# CEC1702 register map
Vendor: Microchip Technology; Series: CEC1702Q; File version: 0
CPU: CM4 r1p0, little endian, MPU, FPU, 3 interrupt priority bits, 155 interrupts
Registers are 32-bit, read-write, reset 0x0 unless marked. A register's access mark holds for its fields unless they carry their own. Offsets are from the block's base; [hi:lo] are bit positions.

## WEEK — The Week Alarm Interface provides two timekeeping functions: a Week Timer and a Sub-Week Timer. Both the Week Timer and the Sub-Week Timer assert the Power-Up Event Output which automatically powers-up the system from the G3 state.
Base 0x4000AC80; register names take the prefix WEEK_
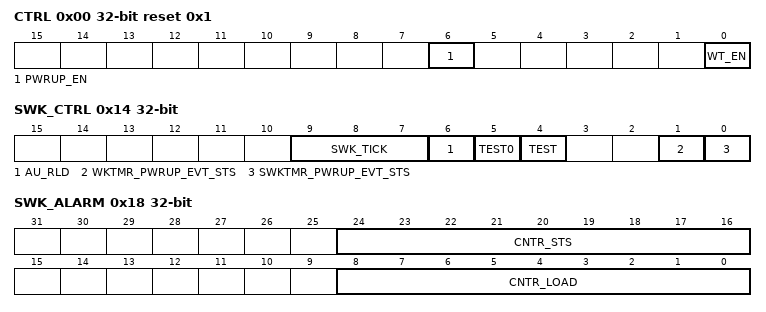
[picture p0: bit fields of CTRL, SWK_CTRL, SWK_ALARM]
0x00 CTRL reset 0x1 — Control Register
  [6] PWRUP_EN — This bit controls the state of the Power-Up Event Output and enables Week POWER-UP Event decoding in the VBAT-Powered Control Interface. 1=Power-Up Event Output Enabled. 0=Power-Up Event Output Disabled and Reset
  [0] WT_EN — The WT_EN bit is used to start and stop the Week Alarm Counter Register and the Clock Divider Register. The value in the Counter Register is held when the WT_ENABLE bit is not asserted (0) and the count is resumed from the last value when the bit is asserted (1). The 15-Bit Clock Divider is reset to 00h and the Week Alarm Interface is in its lowest power consumption state when the WT_ENABLE bit is not asserted.
0x04 ALARM_CNT — Week Alarm Counter Register
  [27:0] WK_CNTR — While the WT_ENABLE bit is 1, this register is incremented at a 1 Hz rate. Writes of this register may require one second to take effect. Reads return the current state of the register. Reads and writes complete independently of the state of WT_ENABLE.
0x08 TMR_COMP reset 0xFFFFFFF — Week Timer Compare Register
  [27:0] WK_COMP — A Week Alarm Interrupt and a Week Alarm Power-Up Event are asserted when the Week Alarm Counter Register is greater than or equal to the contents of this register. Reads and writes complete independently of the state of WT_ENABLE.
0x0C CLKDIV — Clock Divider Register
  [14:0] DIV — Reads of this register return the current state of the Week Timer 15- bit clock divider.
0x10 SS_INTR_SEL — Sub-Second Programmable Interrupt Select Register
  [3:0] SPISR — This field determines the rate at which Sub-Second interrupt events are generated.
0x14 SWK_CTRL ro — Sub-Week Control Register
  [9:7] SWK_TICK — This field selects the clock source for the Sub-Week Counter.
  [6] AU_RLD — 1= No reload occurs when the Sub-Week Counter expires. 0= Reloads the SUBWEEK_COUNTER_LOAD field into the Sub- Week Counter when the counter expires.
  [5] TEST0 — Test
  [4] TEST
  [1] WKTMR_PWRUP_EVT_STS — This bit is set to 1 when the Week Alarm Counter Register is greater than or equal the contents of the Week Timer Compare. Register and the POWERUP_EN is 1. Writes of 1 clear this bit. Writes of 0 have no effect. Note: This bit does not have to be cleared to remove a Week Timer Power-Up Event.
  [0] SWKTMR_PWRUP_EVT_STS — This bit is set to 1 when the Sub-Week Alarm Counter Register decrements from 1 to 0 and the POWERUP_EN is 1. Writes of 1 clear this bit. Writes of 0 have no effect. Note: This bit MUST be cleared to remove a Sub-Week Timer Power-Up Event.
0x18 SWK_ALARM ro — Sub-Week Alarm Counter Register
  [24:16] CNTR_STS — Reads of this register return the current state of the 9-bit Sub-Week Alarm counter.
  [8:0] CNTR_LOAD — Writes with a non-zero value to this field reload the 9-bit Sub-Week Alarm counter. Writes of 0 disable the counter. If the Sub-Week Alarm counter decrements to 0 and the AUTO_RELOAD bit is set, the value in this field is automatically loaded into the Sub-Week Alarm counter.
0x1C BGPO_DATA
  [9:0] BGPO — Battery powered General Purpose Output. Each output pin may be individually configured to be either a VBAT-power BGPO or a VTR powered GPIO, based on the corresponding settings in the BGPO Power Register. Additionally, each output pin may be individually configured to reset to 0 on either RESET_VTR or RESET_SYS, based on the corresponding settings in the BGPO Reset Register. For each bit [i] in the field: 1=BGPO[i] output is high; 0=BGPO[i] output is low.
0x20 BGPO_PWR reset 0x3E — BGPO Power Register
  [5:1] BGPO_POWER — Battery powered General Purpose Output power source. For each bit [i] in the field: 1=BGPO[i] is powered by VBAT. The BGPO[i] pin is always determined by the corresponding bit in the BGPO Data Register. The GPIO Input register for the GPIO that is multiplexed with the BGPO always returns a '1b'. 0=The pin for BGPO[i] functions as a GPIO. When VTR is powered, the pin associated with BGPO[i] is determined by the GPIO associated with the pin. When VTR is unpowered, the pin is tristated.
0x24 BGPO_RST — BGPO Reset Register
  [9:0] BGPO_RESET — Battery powered General Purpose Output reset event. For each bit [i] in the field: 1=BGPO[i] is reset to 0 on RESET_VTR; 0=BGPO[i] is reset to 0 on RESET_SYS.
